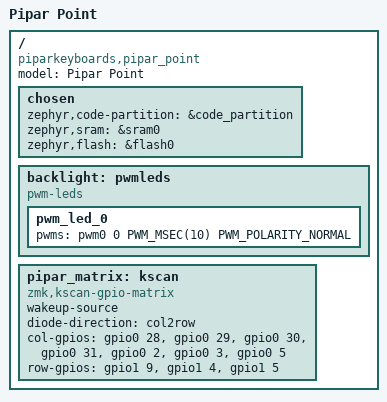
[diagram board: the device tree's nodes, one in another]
/dts-v1/;
#include <nordic/nrf52840_qiaa.dtsi>
#include <common/nordic/nrf52840_uf2_boot_mode.dtsi>
#include <dt-bindings/led/led.h>
#include <dt-bindings/zmk/matrix_transform.h>
#include "pipar_point-pinctrl.dtsi"

/ {
  model = "Pipar Point";
  compatible = "piparkeyboards,pipar_point";

  chosen {
    zephyr,code-partition = &code_partition;
    zephyr,sram = &sram0;
    zephyr,flash = &flash0;
  };

  backlight: pwmleds {
    compatible = "pwm-leds";
    pwm_led_0 {
      pwms = <&pwm0 0 PWM_MSEC(10) PWM_POLARITY_NORMAL>;
    };
  };
  
  pipar_matrix: kscan {
    compatible = "zmk,kscan-gpio-matrix";
    wakeup-source;
    diode-direction = "col2row";
    col-gpios
    = <&gpio0 28 GPIO_ACTIVE_HIGH>
    , <&gpio0 29 GPIO_ACTIVE_HIGH>
    , <&gpio0 30 GPIO_ACTIVE_HIGH>
    , <&gpio0 31 GPIO_ACTIVE_HIGH>
    , <&gpio0 2 GPIO_ACTIVE_HIGH>
    , <&gpio0 3 GPIO_ACTIVE_HIGH>
    , <&gpio0 5 GPIO_ACTIVE_HIGH>
    ;
    row-gpios
    = <&gpio1 9 (GPIO_PULL_DOWN  | GPIO_ACTIVE_HIGH)>
    , <&gpio1 4 (GPIO_PULL_DOWN  | GPIO_ACTIVE_HIGH)>
    , <&gpio1 5 (GPIO_PULL_DOWN  | GPIO_ACTIVE_HIGH)>
    ;
  };
};

#include "pipar_point_nodes.dtsi"

